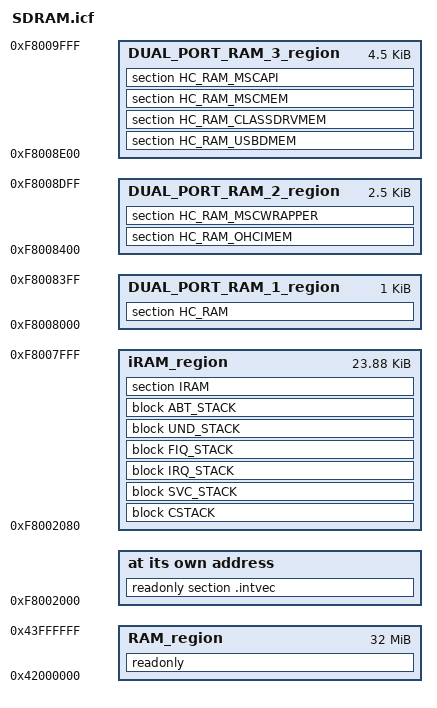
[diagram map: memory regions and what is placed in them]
/*###ICF### Section handled by ICF editor, don't touch! ****/
/*-Editor annotation file-*/
/* IcfEditorFile="$TOOLKIT_DIR$\config\ide\IcfEditor\a_v1_0.xml" */
/*-Specials-*/
define symbol __ICFEDIT_intvec_start__ = 0xF8002000;
/*-Memory Regions-*/
define symbol __ICFEDIT_region_ROM_start__   = 0x00000000;
define symbol __ICFEDIT_region_ROM_end__     = 0x00000000;
define symbol __ICFEDIT_region_RAM_start__   = 0x42000000;
define symbol __ICFEDIT_region_RAM_end__     = 0x43FFFFFF;
/*-Sizes-*/
define symbol __ICFEDIT_size_cstack__   = 0x1000;
define symbol __ICFEDIT_size_svcstack__ = 0x40;
define symbol __ICFEDIT_size_irqstack__ = 0x200;
define symbol __ICFEDIT_size_fiqstack__ = 0x0;
define symbol __ICFEDIT_size_undstack__ = 0x0;
define symbol __ICFEDIT_size_abtstack__ = 0x0;
define symbol __ICFEDIT_size_heap__     = 0x2000;
/**** End of ICF editor section. ###ICF###*/

define memory mem with size = 4G;

define symbol __region_iRAM_start__   = 0xF8002080;
define symbol __region_iRAM_end__     = 0xF8007FFF;

define symbol DUAL_PORT_RAM_1_start   = 0xF8008000;
define symbol DUAL_PORT_RAM_1_end     = 0xF80083FF;
define symbol DUAL_PORT_RAM_2_start   = 0xF8008400;
define symbol DUAL_PORT_RAM_2_end     = 0xF8008DFF;
define symbol DUAL_PORT_RAM_3_start   = 0xF8008E00;
define symbol DUAL_PORT_RAM_3_end     = 0xF8009FFF;

define region ROM_region   = mem:[from __ICFEDIT_region_ROM_start__   to __ICFEDIT_region_ROM_end__];
define region RAM_region   = mem:[from __ICFEDIT_region_RAM_start__   to __ICFEDIT_region_RAM_end__];
define region iRAM_region  = mem:[from __region_iRAM_start__          to __region_iRAM_end__       ];

define region DUAL_PORT_RAM_1_region  = mem:[from DUAL_PORT_RAM_1_start  to DUAL_PORT_RAM_1_end];
define region DUAL_PORT_RAM_2_region  = mem:[from DUAL_PORT_RAM_2_start  to DUAL_PORT_RAM_2_end];
define region DUAL_PORT_RAM_3_region  = mem:[from DUAL_PORT_RAM_3_start  to DUAL_PORT_RAM_3_end];


define block CSTACK    with alignment = 8, size = __ICFEDIT_size_cstack__   { };
define block SVC_STACK with alignment = 8, size = __ICFEDIT_size_svcstack__ { };
define block IRQ_STACK with alignment = 8, size = __ICFEDIT_size_irqstack__ { };
define block FIQ_STACK with alignment = 8, size = __ICFEDIT_size_fiqstack__ { };
define block UND_STACK with alignment = 8, size = __ICFEDIT_size_undstack__ { };
define block ABT_STACK with alignment = 8, size = __ICFEDIT_size_abtstack__ { };
define block HEAP      with alignment = 8, size = __ICFEDIT_size_heap__     { };

initialize by copy { readwrite };
do not initialize  { section .noinit };

// this section is plased into the Built-in RAM3, that is maped on address 0
place at address mem:__ICFEDIT_intvec_start__ { readonly section .intvec };

place in RAM_region   { readonly};

place in RAM_region   { readwrite, block HEAP, block MMUTT {section MMU_TT}};

// this section is plased into the Built-in RAM area
place in iRAM_region   { block CSTACK, block SVC_STACK, block IRQ_STACK,
                         block FIQ_STACK, block UND_STACK, block ABT_STACK, section IRAM};

place in DUAL_PORT_RAM_1_region   { section HC_RAM};
place in DUAL_PORT_RAM_2_region   { section HC_RAM_OHCIMEM, section HC_RAM_MSCWRAPPER
                                  };
place in DUAL_PORT_RAM_3_region   { section HC_RAM_USBDMEM, section HC_RAM_CLASSDRVMEM,
                                    section HC_RAM_MSCMEM, section HC_RAM_MSCAPI
                                  };
